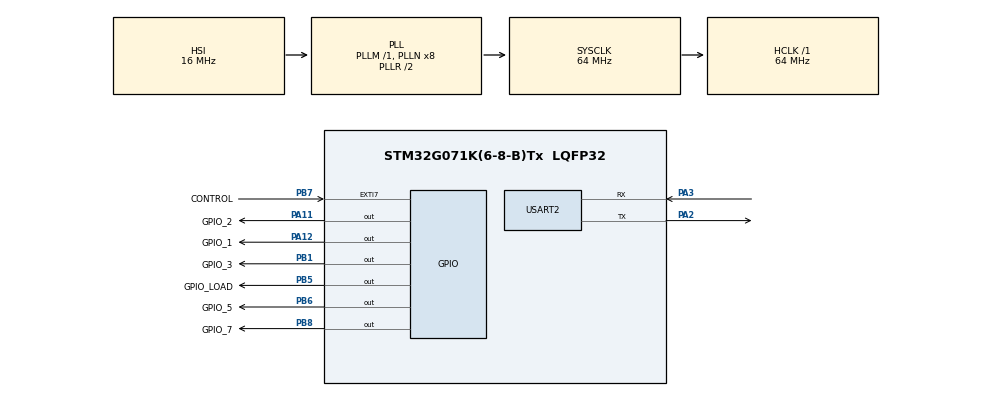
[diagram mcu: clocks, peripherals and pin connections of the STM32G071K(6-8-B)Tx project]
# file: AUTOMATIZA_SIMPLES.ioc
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Mcu.Family=STM32G0
Mcu.Name=STM32G071K(6-8-B)Tx
Mcu.Package=LQFP32
NVIC.EXTI4_15_IRQn=true\:3\:0\:true\:false\:true\:true\:true\:true
NVIC.USART2_IRQn=true\:3\:0\:true\:false\:true\:true\:true\:true
PA11\ [PA9].GPIO_Label=GPIO_2
PA11\ [PA9].PinState=GPIO_PIN_RESET
PA11\ [PA9].Signal=GPIO_Output
PA12\ [PA10].GPIO_Label=GPIO_1
PA12\ [PA10].Signal=GPIO_Output
PA13.Mode=Serial_Wire
PA13.Signal=SYS_SWDIO
PA14-BOOT0.Mode=Serial_Wire
PA14-BOOT0.Signal=SYS_SWCLK
PA2.Mode=Asynchronous
PA2.Signal=USART2_TX
PA3.GPIO_PuPd=GPIO_PULLUP
PA3.Mode=Asynchronous
PA3.Signal=USART2_RX
PB1.GPIO_Label=GPIO_3
PB1.Signal=GPIO_Output
PB5.GPIO_Label=GPIO_LOAD
PB5.Signal=GPIO_Output
PB6.GPIO_Label=GPIO_5
PB6.Signal=GPIO_Output
PB7.GPIO_Label=CONTROL
PB7.GPIO_ModeDefaultEXTI=GPIO_MODE_IT_FALLING
PB7.GPIO_PuPd=GPIO_NOPULL
PB7.Signal=GPXTI7
PB8.GPIO_Label=GPIO_7
PB8.Signal=GPIO_Output
ProjectManager.HeapSize=0x200
ProjectManager.StackSize=0x400
ProjectManager.TargetToolchain=STM32CubeIDE
RCC.ADCFreq_Value=64000000
RCC.AHBFreq_Value=64000000
RCC.CortexFreq_Value=64000000
RCC.EXTERNAL_CLOCK_VALUE=48000
RCC.HCLKFreq_Value=64000000
RCC.HSE_VALUE=8000000
RCC.HSI_VALUE=16000000
RCC.LSE_VALUE=32768
RCC.SYSCLKFreq_VALUE=64000000
RCC.SYSCLKSource=RCC_SYSCLKSOURCE_PLLCLK
RCC.VCOOutputFreq_Value=128000000
USART2.VirtualMode-Asynchronous=VM_ASYNC
VP_IWDG_VS_IWDG.Mode=IWDG_Activate
VP_SYS_VS_DBSignals.Mode=DisableDeadBatterySignals
board=custom

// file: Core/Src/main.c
/* USER CODE BEGIN Header */
/**
  ******************************************************************************
  * @file           : main.c
  * @brief          : Main program body
  ******************************************************************************
  * @attention
  *
  * Copyright (c) 2023 STMicroelectronics.
  * All rights reserved.
  *
  * This software is licensed under terms that can be found in the LICENSE file
  * in the root directory of this software component.
  * If no LICENSE file comes with this software, it is provided AS-IS.
  *
  ******************************************************************************
  */
/* USER CODE END Header */
#include "main.h"

IWDG_HandleTypeDef hiwdg;

UART_HandleTypeDef huart2;

void SystemClock_Config(void);
static void MX_GPIO_Init(void);
static void MX_USART2_UART_Init(void);
static void MX_IWDG_Init(void);

int main(void)
{
  /* USER CODE BEGIN 1 */
//	uint32_t delay = 0;
//	const uint8_t pdata[] = {"\r\n TOOGLE LOAD\r\n"};

  /* USER CODE END 1 */

  /* MCU Configuration--------------------------------------------------------*/

  /* Reset of all peripherals, Initializes the Flash interface and the Systick. */
  HAL_Init();

  /* Configure the system clock */
  SystemClock_Config();

  /* Initialize all configured peripherals */
  MX_GPIO_Init();
  MX_USART2_UART_Init();
  MX_IWDG_Init();
  /* USER CODE BEGIN 2 */
//  HAL_UART_Init(&huart2);
  loadControlInitialize();
  /* USER CODE END 2 */

  /* Infinite loop */
  /* USER CODE BEGIN WHILE */
  while (1)
  {
	  HAL_IWDG_Refresh(&hiwdg);
    /* USER CODE END WHILE */

  }
}

void SystemClock_Config(void)
{
  RCC_OscInitTypeDef RCC_OscInitStruct = {0};
  RCC_ClkInitTypeDef RCC_ClkInitStruct = {0};

  /** Configure the main internal regulator output voltage
  */
  HAL_PWREx_ControlVoltageScaling(PWR_REGULATOR_VOLTAGE_SCALE1);

  /** Initializes the RCC Oscillators according to the specified parameters
  * in the RCC_OscInitTypeDef structure.
  */
  RCC_OscInitStruct.OscillatorType = RCC_OSCILLATORTYPE_HSI|RCC_OSCILLATORTYPE_LSI;
  RCC_OscInitStruct.HSIState = RCC_HSI_ON;
  RCC_OscInitStruct.HSIDiv = RCC_HSI_DIV1;
  RCC_OscInitStruct.HSICalibrationValue = RCC_HSICALIBRATION_DEFAULT;
  RCC_OscInitStruct.LSIState = RCC_LSI_ON;
  RCC_OscInitStruct.PLL.PLLState = RCC_PLL_ON;
  RCC_OscInitStruct.PLL.PLLSource = RCC_PLLSOURCE_HSI;
  RCC_OscInitStruct.PLL.PLLM = RCC_PLLM_DIV1;
  RCC_OscInitStruct.PLL.PLLN = 8;
  RCC_OscInitStruct.PLL.PLLP = RCC_PLLP_DIV2;
  RCC_OscInitStruct.PLL.PLLQ = RCC_PLLQ_DIV2;
  RCC_OscInitStruct.PLL.PLLR = RCC_PLLR_DIV2;
  if (HAL_RCC_OscConfig(&RCC_OscInitStruct) != HAL_OK)
  {
    Error_Handler();
  }

  /** Initializes the CPU, AHB and APB buses clocks
  */
  RCC_ClkInitStruct.ClockType = RCC_CLOCKTYPE_HCLK|RCC_CLOCKTYPE_SYSCLK
                              |RCC_CLOCKTYPE_PCLK1;
  RCC_ClkInitStruct.SYSCLKSource = RCC_SYSCLKSOURCE_PLLCLK;
  RCC_ClkInitStruct.AHBCLKDivider = RCC_SYSCLK_DIV1;
  RCC_ClkInitStruct.APB1CLKDivider = RCC_HCLK_DIV1;

  if (HAL_RCC_ClockConfig(&RCC_ClkInitStruct, FLASH_LATENCY_2) != HAL_OK)
  {
    Error_Handler();
  }
}

static void MX_IWDG_Init(void)
{

  hiwdg.Instance = IWDG;
  hiwdg.Init.Prescaler = IWDG_PRESCALER_4;
  hiwdg.Init.Window = 4095;
  hiwdg.Init.Reload = 4095;
  if (HAL_IWDG_Init(&hiwdg) != HAL_OK)
  {
    Error_Handler();
  }

}

static void MX_USART2_UART_Init(void)
{

  huart2.Instance = USART2;
  huart2.Init.BaudRate = 115200;
  huart2.Init.WordLength = UART_WORDLENGTH_8B;
  huart2.Init.StopBits = UART_STOPBITS_1;
  huart2.Init.Parity = UART_PARITY_NONE;
  huart2.Init.Mode = UART_MODE_TX_RX;
  huart2.Init.HwFlowCtl = UART_HWCONTROL_NONE;
  huart2.Init.OverSampling = UART_OVERSAMPLING_16;
  huart2.Init.OneBitSampling = UART_ONE_BIT_SAMPLE_DISABLE;
  huart2.Init.ClockPrescaler = UART_PRESCALER_DIV1;
  huart2.AdvancedInit.AdvFeatureInit = UART_ADVFEATURE_NO_INIT;
  if (HAL_UART_Init(&huart2) != HAL_OK)
  {
    Error_Handler();
  }
  if (HAL_UARTEx_SetTxFifoThreshold(&huart2, UART_TXFIFO_THRESHOLD_1_8) != HAL_OK)
  {
    Error_Handler();
  }
  if (HAL_UARTEx_SetRxFifoThreshold(&huart2, UART_RXFIFO_THRESHOLD_1_8) != HAL_OK)
  {
    Error_Handler();
  }
  if (HAL_UARTEx_DisableFifoMode(&huart2) != HAL_OK)
  {
    Error_Handler();
  }

}

static void MX_GPIO_Init(void)
{
  GPIO_InitTypeDef GPIO_InitStruct = {0};

  /* GPIO Ports Clock Enable */
  __HAL_RCC_GPIOA_CLK_ENABLE();
  __HAL_RCC_GPIOB_CLK_ENABLE();

  /*Configure GPIO pin Output Level */
  HAL_GPIO_WritePin(GPIOB, GPIO_3_Pin|GPIO_LOAD_Pin|GPIO_5_Pin|GPIO_7_Pin, GPIO_PIN_RESET);

  /*Configure GPIO pin Output Level */
  HAL_GPIO_WritePin(GPIOA, GPIO_2_Pin|GPIO_1_Pin, GPIO_PIN_RESET);

  /*Configure GPIO pins : GPIO_3_Pin GPIO_LOAD_Pin GPIO_5_Pin GPIO_7_Pin */
  GPIO_InitStruct.Pin = GPIO_3_Pin|GPIO_LOAD_Pin|GPIO_5_Pin|GPIO_7_Pin;
  GPIO_InitStruct.Mode = GPIO_MODE_OUTPUT_PP;
  GPIO_InitStruct.Pull = GPIO_NOPULL;
  GPIO_InitStruct.Speed = GPIO_SPEED_FREQ_LOW;
  HAL_GPIO_Init(GPIOB, &GPIO_InitStruct);

  /*Configure GPIO pins : GPIO_2_Pin GPIO_1_Pin */
  GPIO_InitStruct.Pin = GPIO_2_Pin|GPIO_1_Pin;
  GPIO_InitStruct.Mode = GPIO_MODE_OUTPUT_PP;
  GPIO_InitStruct.Pull = GPIO_NOPULL;
  GPIO_InitStruct.Speed = GPIO_SPEED_FREQ_LOW;
  HAL_GPIO_Init(GPIOA, &GPIO_InitStruct);

  /*Configure GPIO pin : CONTROL_Pin */
  GPIO_InitStruct.Pin = CONTROL_Pin;
  GPIO_InitStruct.Mode = GPIO_MODE_IT_FALLING;
  GPIO_InitStruct.Pull = GPIO_NOPULL;
  HAL_GPIO_Init(CONTROL_GPIO_Port, &GPIO_InitStruct);

  /* EXTI interrupt init*/
  HAL_NVIC_SetPriority(EXTI4_15_IRQn, 3, 0);
  HAL_NVIC_EnableIRQ(EXTI4_15_IRQn);

}

void Error_Handler(void)
{
  __disable_irq();
  while (1)
  {
  }
}
